# RZN2H register map
Vendor: Renesas Electronics Corporation; Series: RZN; File version: 1.00.00
CPU: other r0p0, little endian, MPU, no FPU, VTOR, 4 interrupt priority bits, 624 interrupts
Registers are 32-bit, read-write, reset 0x0 unless marked. A register's access mark holds for its fields unless they carry their own. Offsets are from the block's base; [hi:lo] are bit positions; 'fields as' and 'values as' point back to an identical list.

## MTU8 — Multi-Function Timer Pulse Unit Channel 8
Base 0x90001600
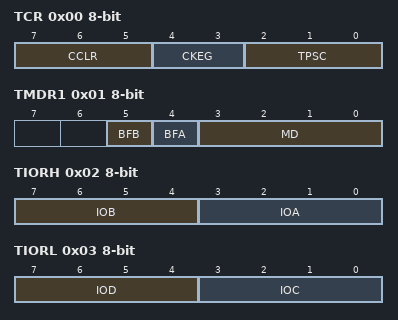
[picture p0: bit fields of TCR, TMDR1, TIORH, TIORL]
0x00 TCR 8-bit — Timer Control Register
  [7:5] CCLR — Counter Clear Source Select
  [4:3] CKEG — Clock Edge Select
    0=Count at rising edge; 1=Count at falling edge; 0b1x=Count at both edges
  [2:0] TPSC — Time Prescaler Select
0x01 TMDR1 8-bit — Timer Mode Register 1
  [5] BFB — Buffer Operation B
    0=TGRB and TGRD operate normally; 1=TGRB and TGRD used together for buffer operation
  [4] BFA — Buffer Operation A
    0=TGRA and TGRC operate normally; 1=TGRA and TGRC used together for buffer operation
  [3:0] MD — Mode Select
0x02 TIORH 8-bit — Timer I/O Control Register H
  [7:4] IOB — I/O Control B
  [3:0] IOA — I/O Control A
0x03 TIORL 8-bit — Timer I/O Control Register L
  [7:4] IOD — I/O Control B
  [3:0] IOC — I/O Control A
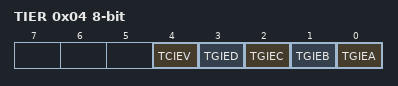
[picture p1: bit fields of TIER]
0x04 TIER 8-bit — Timer Interrupt Enable Register
  [4] TCIEV — Overflow Interrupt Enable
    0=Interrupt requests (TCIV) disabled; 1=Interrupt requests (TCIV) enabled
  [3] TGIED — TGR Interrupt Enable D
    0=Interrupt requests (TGID) disabled; 1=Interrupt requests (TGID) enabled
  [2] TGIEC — TGR Interrupt Enable C
    0=Interrupt requests (TGIC) disabled; 1=Interrupt requests (TGIC) enabled
  [1] TGIEB — TGR Interrupt Enable B
    0=Interrupt requests (TGIB) disabled; 1=Interrupt requests (TGIB) enabled
  [0] TGIEA — TGR Interrupt Enable A
    0=Interrupt requests (TGIA) disabled; 1=Interrupt requests (TGIA) enabled
0x06 TCR2 8-bit — Timer Control Register 2
  [2:0] TPSC2 — Time Prescaler Select
0x08 TCNT — Timer Counter
0x0C TGRA reset 0xFFFFFFFF — Timer General Register A
0x10 TGRB reset 0xFFFFFFFF — Timer General Register B
0x14 TGRC reset 0xFFFFFFFF — Timer General Register C
0x18 TGRD reset 0xFFFFFFFF — Timer General Register D

## MTU5 — Multi-Function Timer Pulse Unit Channel 5
Base 0x90001C00
0x80 TCNTU 16-bit — Timer Counter U
0x82 TGRU 16-bit reset 0xFFFF — Timer General Register U
0x84 TCRU 8-bit — Timer Control Register U
  [1:0] TPSC — Time Prescaler Select
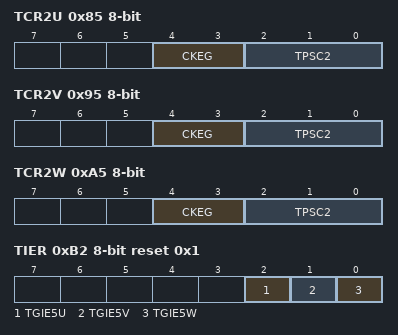
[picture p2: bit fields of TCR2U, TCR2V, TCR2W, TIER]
0x85 TCR2U 8-bit — Timer Control Register 2U
  [4:3] CKEG — Clock Edge Select
    0=Counts at the rising edge; 1=Counts at the falling edge; 0b1x=Counts at both edges
  [2:0] TPSC2 — Time Prescaler Select
0x86 TIORU 8-bit — Timer I/O Control Register U
  [4:0] IOC — I/O Control C
0x90 TCNTV 16-bit — Timer Counter V
0x92 TGRV 16-bit reset 0xFFFF — Timer General Register V
0x94 TCRV 8-bit — Timer Control Register V
  [1:0] TPSC — Time Prescaler Select
0x95 TCR2V 8-bit — Timer Control Register 2V
  fields as TCR2U
0x96 TIORV 8-bit — Timer I/O Control Register V
  [4:0] IOC — I/O Control C
0xA0 TCNTW 16-bit — Timer Counter W
0xA2 TGRW 16-bit reset 0xFFFF — Timer General Register W
0xA4 TCRW 8-bit — Timer Control Register W
  [1:0] TPSC — Time Prescaler Select
0xA5 TCR2W 8-bit — Timer Control Register 2W
  fields as TCR2U
0xA6 TIORW 8-bit — Timer I/O Control Register W
  [4:0] IOC — I/O Control C
0xB2 TIER 8-bit reset 0x1 — Timer Interrupt Enable Register
  [2] TGIE5U — TGR Interrupt Enable 5U
    0=Interrupt requests TGIU5 disabled; 1=Interrupt requests TGIU5 enabled
  [1] TGIE5V — TGR Interrupt Enable 5V
    0=Interrupt requests TGIV5 disabled; 1=Interrupt requests TGIV5 enabled
  [0] TGIE5W — TGR Interrupt Enable 5W
    0=Interrupt requests TGIW5 disabled; 1=Interrupt requests TGIW5 enabled
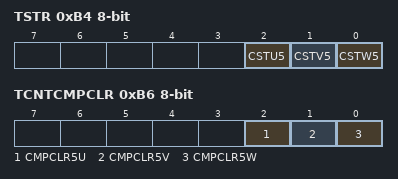
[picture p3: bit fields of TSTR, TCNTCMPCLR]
0xB4 TSTR 8-bit — Timer Start Register
  [2] CSTU5 — Counter Start U5
    0=MTU5.TCNTU counting is stopped; 1=MTU5.TCNTU performs count operation
  [1] CSTV5 — Counter Start V5
    0=MTU5.TCNTV counting is stopped; 1=MTU5.TCNTV performs count operation
  [0] CSTW5 — Counter Start W5
    0=MTU5.TCNTW counting is stopped; 1=MTU5.TCNTW performs count operation
0xB6 TCNTCMPCLR 8-bit — Timer Compare Match Clear Register
  [2] CMPCLR5U — TCNT Compare Clear 5U
    0=Disables MTU5.TCNTU to be cleared to 0x0000 at MTU5.TCNTU and MTU5.TGRU compare match or input capture; 1=Enables MTU5.TCNTU to be cleared to 0x0000 at MTU5.TCNTU and MTU5.TGRU compare match or input capture
  [1] CMPCLR5V — TCNT Compare Clear 5V
    0=Disables MTU5.TCNTV to be cleared to 0x0000 at MTU5.TCNTV and MTU5.TGRV compare match or input capture; 1=Enables MTU5.TCNTV to be cleared to 0x0000 at MTU5.TCNTV and MTU5.TGRV compare match or input capture
  [0] CMPCLR5W — TCNT Compare Clear 5W
    0=Disables MTU5.TCNTW to be cleared to 0x0000 at MTU5.TCNTW and MTU5.TGRW compare match or input capture; 1=Enables MTU5.TCNTW to be cleared to 0x0000 at MTU5.TCNTW and MTU5.TGRW compare match or input capture
